# R7FA8M1AH register map
Vendor: Renesas; Series: RA8; File version: 1.2
CPU: CM85 r0p0, little endian, MPU, FPU, VTOR, 4 interrupt priority bits
Registers are 32-bit, read-write, reset 0x0 unless marked. A register's access mark holds for its fields unless they carry their own. Offsets are from the block's base; [hi:lo] are bit positions; {n}, {i} and the like mark numbered series; 'fields as' and 'values as' point back to an identical list.

## USBHS — USB 2.0 High-Speed Module
Base 0x40351000
Same registers: USBHS_NS 0x50351000
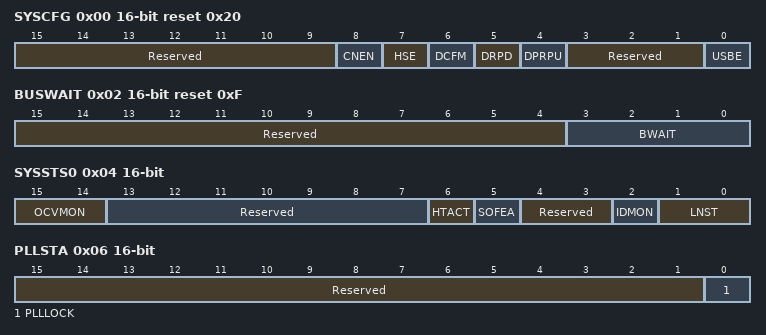
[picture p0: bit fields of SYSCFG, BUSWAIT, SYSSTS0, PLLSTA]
0x00 SYSCFG 16-bit reset 0x20 — System Configuration Control Register
  [15:9] Reserved — These bits are read as 0000000. The write value should be 0000000.
  [8] CNEN — Single End Receiver Enable
    0=Single end receiver operation is disabled; 1=Single end receiver operation is enabled
  [7] HSE — High-Speed Operation Enable
    0=High-speed operation is disabled.(When the function controller function is selected: Full speed, When the host controller function is selected: Full/low speed); 1=High-speed operation is enabled (the controller detects the communication speed)
  [6] DCFM — Controller Function Select
    0=Function controller function is selected; 1=Host controller function is selected
  [5] DRPD — D+/D- Line Resistor Control
    0=Pulling down the line is disabled; 1=Pulling down the line is enabled
  [4] DPRPU — D+ Line Resistor Control
    0=Pulling up the line is disabled; 1=Pulling up the line is enabled
  [3:1] Reserved — These bits are read as 000. The write value should be 000.
  [0] USBE — USB Operation Enable
    0=USB operation is disabled; 1=USB operation is enabled
0x02 BUSWAIT 16-bit reset 0xF (reset mask 0x3F3F) — CPU Bus Wait Register
  [15:4] Reserved — These bits are read as 000000000000. The write value should be 000000000000.
  [3:0] BWAIT — CPU Bus Access Wait Specification BWAIT waits (BWAIT+2 access cycles)
    other=BWAIT (BWAIT wait(s) ( BWAIT + 2 access cycles ))
0x04 SYSSTS0 16-bit ro reset not defined — System Configuration Status Register
  [15:14] OCVMON — External USB1_OVRCURA/USB1_OVRCURB Input Pin MonitorThe OCVMON[1] bit indicates the status of the USBHS_OVRCURA pin. The OCVMON[0] bit indicates the status of the USBHS_OVRCURB pin.
  [13:7] Reserved — These bits are read as 0000000.
  [6] HTACT — Host Sequencer Status Monitor
    0=Host sequencer is stopped; 1=Host sequencer is operating
  [5] SOFEA — SOF Active Monitor While Host Controller Function is Selected.
    0=SOF output is stopped; 1=SOF output is operating
  [4:3] Reserved — These bits are read as 00.
  [2] IDMON — ID0 Pin Monitor
    0=ID0 = Low; 1=ID0 = High
  [1:0] LNST — USB Data Line Status Monitor
    0=SE0 (During Low-Speed Operation:only when the host controller function is selected or During Full-Speed Operation) /Squelch (During Hi-Speed Operation or During Chirp Operation); 1=K-State (During Low-Speed Operation:only when the host controller function is selected) /J-State (During Full-Speed Operation) /Unsquelch (During Hi-Speed Operation) /Chirp J (During Chirp Operation); 2=J-State (During Low-Speed Operation:only when the host controller function is selected) /K-State (During Full-Speed Operation) /Invalid (During Hi-Speed Operation) /Chirp K (During Chirp Operation); 3=SE1 (During Low-Speed Operation:only when the host controller function is selected or During Full-Speed Operation) /Invalid (During Hi-Speed Operation or During Chirp Operation)
0x06 PLLSTA 16-bit ro (reset mask 0x1) — PLL Status Register
  [15:1] Reserved — These bits are read as 000000000000000.
  [0] PLLLOCK — PLL Lock Flag
    0=PLL is not locked; 1=PLL is locked
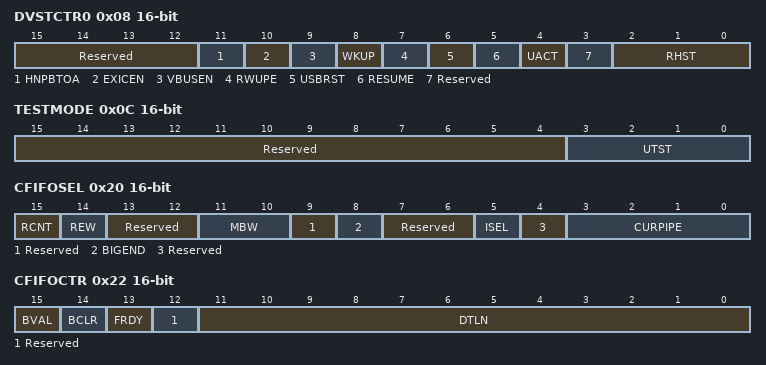
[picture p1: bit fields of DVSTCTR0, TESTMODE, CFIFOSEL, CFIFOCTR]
0x08 DVSTCTR0 16-bit (reset mask 0x7F7) — Device State Control Register 0
  [15:12] Reserved — These bits are read as 0000. The write value should be 0000.
  [11] HNPBTOA — Host Negotiation Protocol (HNP) Control This bit is used when switching from device B to device A while in OTG mode. If the HNPBTOA bit is 1, the internal function control keeps the suspended state until the HNP processing ends even though SYSCFG.DPRPU = 0 or SYSCFG.DCFM = 1 is set.
    0=Normal Operation; 1=Switching from device B to device A is enabled
  [10] EXICEN — USB0_EXICEN Output Pin ControlThe EXICEN bit value is output as the status of the external USB0_EXICEN pin without change.
  [9] VBUSEN — USB0_VBUSEN Output Pin ControlThe VBUSEN bit value is output as the status of the external USB0_VBUSEN pin without change.
  [8] WKUP — Wakeup Output
    0=Remote wakeup signal is not output; 1=Remote wakeup signal is output
  [7] RWUPE — Remote Wakeup Detection Enable
    0=Downstream-port remote wakeup is disabled; 1=Downstream-port remote wakeup is enabled
  [6] USBRST — USB Bus Reset Output
    0=USB bus reset signal is not output; 1=USB bus reset signal is output
  [5] RESUME — Resume Output
    0=Resume signal is not output; 1=Resume signal is output
  [4] UACT — USB Bus Enable
    0=Downstream port is disabled (SOF or micro-SOF transmission is disabled); 1=Downstream port is enabled (SOF or micro-SOF transmission is enabled)
  [3] Reserved — This bit is read as 0. The write value should be 0.
  [2:0] RHST ro — USB Bus Reset Status
    0=Communication speed not determined; 1=Low-speed connection(When the host controller function is selected) /USB bus reset in progress or low-speed connection(When the function controller function is selected); 2=Full-speed connection(When the host controller function is selected) /USB bus reset in progress or full-speed connection(When the function controller function is selected); 3=Setting prohibited; other=others (USB bus reset in progress(When the host controller function is selected))
0x0C TESTMODE 16-bit (reset mask 0xF) — USB Test Mode Register
  [15:4] Reserved — These bits are read as 000000000000. The write value should be 000000000000.
  [3:0] UTST — Test Mode
    0=Normal operation; 1=Test_J TestMode(When the Function Controller Function is Selected); 2=Test_K TestMode(When the Function Controller Function is Selected); 3=Test_SE0_NAK TestMode(When the Function Controller Function is Selected); 4=Test_Packet TestMode(When the Function Controller Function is Selected); 5=Reserved TestMode(When the Function Controller Function is Selected); 6=Reserved TestMode(When the Function Controller Function is Selected); 7=Reserved TestMode(When the Function Controller Function is Selected); 9=Test_J TestMode(When the Host Controller Function is Selected); 10=Test_K TestMode(When the Host Controller Function is Selected); 11=Test_SE0_NAK TestMode(When the Host Controller Function is Selected); 12=Test_Packet TestMode(When the Host Controller Function is Selected); 13=Test_Force_EnableTestMode(When the Host Controller Function is Selected); 14=Reserved TestMode(When the Host Controller Function is Selected); 15=Reserved TestMode(When the Host Controller Function is Selected)
0x14 CFIFO — CFIFO Port Register
  [31:0] FIFOPORT — FIFO Port.Read receive data from the FIFO buffer or write transmit data to the FIFO buffer by accessing these bits.
0x14 CFIFOL 16-bit (alternate view of CFIFO) — CFIFO Port Register L
0x14 CFIFOLL 8-bit (alternate view of CFIFOL) — CFIFO Port Register LL
0x16 CFIFOH 16-bit (alternate view of CFIFO) — CFIFO Port Register H
0x17 CFIFOHH 8-bit (alternate view of CFIFOH) — CFIFO Port Register HH
0x18 D0FIFO — D0FIFO Port Register
  [31:0] FIFOPORT — FIFO Port Read receive data from the FIFO buffer or write transmit data to the FIFO buffer by accessing these bits.
0x18 D0FIFOL 16-bit (alternate view of D0FIFO) — D0FIFO Port Register L
0x18 D0FIFOLL 8-bit (alternate view of D0FIFOL) — D0FIFO Port Register LL
0x1A D0FIFOH 16-bit (alternate view of D0FIFO) — D0FIFO Port Register H
0x1B D0FIFOHH 8-bit (alternate view of D0FIFOH) — D0FIFO Port Register HH
0x1C D1FIFO — D1FIFO Port Register
  [31:0] FIFOPORT — FIFO PortRead receive data from the FIFO buffer or write transmit data to the FIFO buffer by accessing these bits.
0x1C D1FIFOL 16-bit (alternate view of D1FIFO) — D1FIFO Port Register L
0x1C D1FIFOLL 8-bit (alternate view of D1FIFOL) — D1FIFO Port Register LL
0x1E D1FIFOH 16-bit (alternate view of D1FIFO) — D1FIFO Port Register H
0x1F D1FIFOHH 8-bit (alternate view of D1FIFOH) — D1FIFO Port Register HH
0x20 CFIFOSEL 16-bit (reset mask 0xCD27) — CFIFO Port Select Register
  [15] RCNT — Read Count Mode
    0=The DTLN bits are cleared when all of the receive data has been read from the CFIFO; 1=The DTLN bits are decremented each time the receive data is read from the CFIFO
  [14] REW wo — Buffer Pointer Rewind
    0=Do not rewind buffer pointer (Writing 0 has no effect.); 1=Rewind buffer pointer
  [13:12] Reserved — These bits are read as 00. The write value should be 00.
  [11:10] MBW — CFIFO Port Access Bit Width
    0=8-bit width; 1=16-bit width; 2=32-bit width; 3=Setting prohibited
  [9] Reserved — This bit is read as 0. The write value should be 0.
  [8] BIGEND — FIFO Port Endian Control
    0=Little endian; 1=Big endian
  [7:6] Reserved — These bits are read as 00. The write value should be 00.
  [5] ISEL — FIFO Port Access Direction when DCP is Selected
    0=Reading from the buffer memory is selected; 1=Writing to the buffer memory is selected
  [4] Reserved — This bit is read as 0. The write value should be 0.
  [3:0] CURPIPE — FIFO Port Access Pipe Specification
    0=DCP; {v}=PIPE{v} (v=1..9); other=others (Setting prohibited)
0x22 CFIFOCTR 16-bit (reset mask 0xEFFE) — CFIFO Port Control Register
  [15] BVAL — Buffer Memory Valid Flag
    0=Invalid; 1=Writing ended
  [14] BCLR wo — CPU Buffer Clear
    0=No operation; 1=Clear FIFO buffer on the CPU side
  [13] FRDY ro — FIFO Port ReadyIndicates whether the FIFO port can be accessed.
    0=FIFO port access is disabled; 1=FIFO port access is enabled
  [12] Reserved — This bit is read as 0. The write value should be 0.
  [11:0] DTLN ro — Receive Data Length.Indicates the length of the receive data.
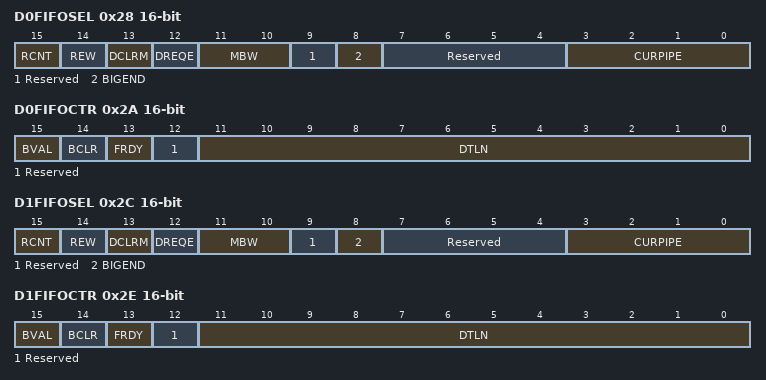
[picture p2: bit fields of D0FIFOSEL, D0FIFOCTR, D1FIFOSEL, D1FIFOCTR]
0x28 D0FIFOSEL 16-bit (reset mask 0xFD07) — D0FIFO Port Select Register
  [15] RCNT — Read Count Mode
    values as CFIFOSEL.RCNT
  [14] REW wo — Buffer Pointer Rewind
    0=The buffer pointer is not rewound; 1=The buffer pointer is rewound
  [13] DCLRM — Auto Buffer Memory Clear Mode Accessed after Specified Pipe Data is Read
    0=Auto buffer clear mode is disabled; 1=Auto buffer clear mode is enabled
  [12] DREQE — UCL_Dx_DREQ Signal Output Enable
    0=Disables the output; 1=Enables the output
  [11:10] MBW — FIFO Port Access Bit Width
    values as CFIFOSEL.MBW
  [9] Reserved — This bit is read as 0. The write value should be 0.
  [8] BIGEND — FIFO Port Endian Control
    0=Little endian; 1=Big endian
  [7:4] Reserved — These bits are read as 0000. The write value should be 0000.
  [3:0] CURPIPE — FIFO Port Access Pipe Specification
    0=No pipe specified; 1=Pipe1; {v}=Pipe {v} (v=2..9); other=others (Setting prohibited)
0x2A D0FIFOCTR 16-bit (reset mask 0xEFFE) — D0FIFO Port Control Register
  fields as CFIFOCTR
0x2C D1FIFOSEL 16-bit (reset mask 0xFD07) — D1FIFO Port Select Register
  [15] RCNT — Read Count Mode
    values as CFIFOSEL.RCNT
  [14] REW wo — Buffer Pointer Rewind
    values as D0FIFOSEL.REW
  [13] DCLRM — Auto Buffer Memory Clear Mode Accessed after Specified Pipe Data is Read
    values as D0FIFOSEL.DCLRM
  [12] DREQE — UCL_Dx_DREQ Signal Output Enable
    0=Disables the output; 1=Enables the output
  [11:10] MBW — FIFO Port Access Bit Width
    values as CFIFOSEL.MBW
  [9] Reserved — This bit is read as 0. The write value should be 0.
  [8] BIGEND — FIFO Port Endian Control
    0=Little endian; 1=Big endian
  [7:4] Reserved — These bits are read as 0000. The write value should be 0000.
  [3:0] CURPIPE — FIFO Port Access Pipe Specification
    0=No pipe specified; {v}=Pipe {v} (v=1..9); other=others (Setting prohibited)
0x2E D1FIFOCTR 16-bit (reset mask 0xEFFE) — D1FIFO Port Control Register
  fields as CFIFOCTR
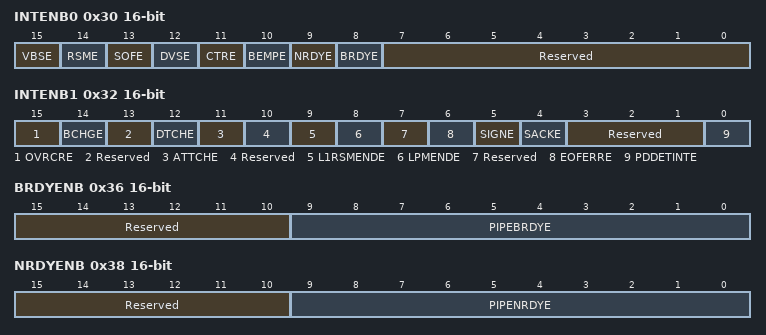
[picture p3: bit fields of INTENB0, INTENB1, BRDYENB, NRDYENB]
0x30 INTENB0 16-bit (reset mask 0xFF00) — Interrupt Enable Register 0
  [15] VBSE — VBUS Interrupt Enable
    0=Interrupt output disabled; 1=Interrupt output enabled
  [14] RSME — Resume Interrupt Enable
    0=Interrupt output disabled; 1=Interrupt output enabled
  [13] SOFE — Frame Number Update Interrupt Enable
    0=Interrupt output disabled; 1=Interrupt output enabled
  [12] DVSE — Device State Transition Interrupt Enable
    0=Interrupt output disabled; 1=Interrupt output enabled
  [11] CTRE — Control Transfer Stage Transition Interrupt Enable
    0=Interrupt output disabled; 1=Interrupt output enabled
  [10] BEMPE — Buffer Empty Interrupt Enable
    0=Interrupt output disabled; 1=Interrupt output enabled
  [9] NRDYE — Buffer Not Ready Response Interrupt Enable
    0=Interrupt output disabled; 1=Interrupt output enabled
  [8] BRDYE — Buffer Ready Interrupt Enable
    0=Interrupt output disabled; 1=Interrupt output enabled
  [7:0] Reserved — These bits are read as 00000000. The write value should be 00000000.
0x32 INTENB1 16-bit (reset mask 0xDB71) — Interrupt Enable Register 1
  [15] OVRCRE — OVRCRE Interrupt Enable
    0=Interrupt output disabled; 1=Interrupt output enabled
  [14] BCHGE — USB Bus Change Interrupt Enable
    0=Interrupt output disabled; 1=Interrupt output enabled
  [13] Reserved — This bit is read as 0. The write value should be 0.
  [12] DTCHE — Disconnection Detection Interrupt Enable
    0=Interrupt output disabled; 1=Interrupt output enabled
  [11] ATTCHE — Connection Detection Interrupt Enable
    0=Interrupt output disabled; 1=Interrupt output enabled
  [10] Reserved — This bit is read as 0. The write value should be 0.
  [9] L1RSMENDE — L1 Resume End Interrupt Enable
    0=Interrupt output disabled; 1=Interrupt output enabled
  [8] LPMENDE — LPM Transaction End Interrupt Enable
    0=Interrupt output disabled; 1=Interrupt output enabled
  [7] Reserved — This bit is read as 0. The write value should be 0.
  [6] EOFERRE — EOF Error Detection Interrupt Enable
    0=Interrupt output disabled; 1=Interrupt output enabled
  [5] SIGNE — Setup Transaction Error Interrupt Enable
    0=Interrupt output disabled; 1=Interrupt output enabled
  [4] SACKE — Setup Transaction Normal Response Interrupt Enable
    0=Interrupt output disabled; 1=Interrupt output enabled
  [3:1] Reserved — These bits are read as 000. The write value should be 000.
  [0] PDDETINTE — PDDETINT Detection Interrupt Enable
    0=Interrupt output disabled; 1=Interrupt output enabled
0x36 BRDYENB 16-bit — BRDY Interrupt Enable Register
  [15:10] Reserved — These bits are read as 000000. The write value should be 000000.
  [9:0] PIPEBRDYE — BRDY Interrupt Enable for Each Pipe
    0=Interrupt output disabled; 1=Interrupt output enabled
0x38 NRDYENB 16-bit — NRDY Interrupt Enable Register
  [15:10] Reserved — These bits are read as 000000. The write value should be 000000.
  [9:0] PIPENRDYE — NRDY Interrupt Enable for Each Pipe
    0=Interrupt output disabled; 1=Interrupt output enabled
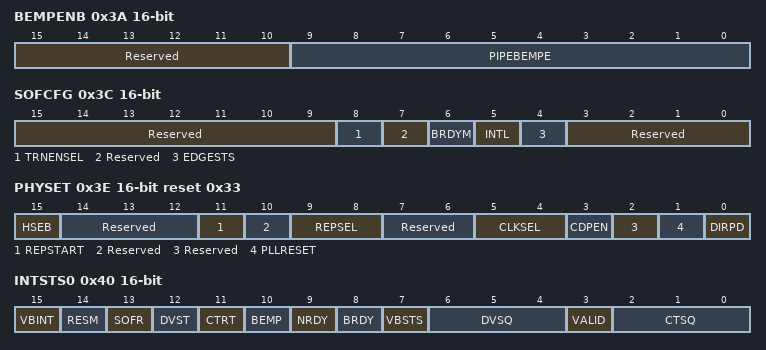
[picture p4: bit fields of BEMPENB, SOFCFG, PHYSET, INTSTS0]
0x3A BEMPENB 16-bit — BEMP Interrupt Enable Register
  [15:10] Reserved — These bits are read as 000000. The write value should be 000000.
  [9:0] PIPEBEMPE — BEMP Interrupt Enable for Each Pipe
    0=Interrupt output disabled; 1=Interrupt output enabled
0x3C SOFCFG 16-bit (reset mask 0x170) — SOF Pin Configuration Register
  [15:9] Reserved — These bits are read as 0000000. The write value should be 0000000.
  [8] TRNENSEL — Transaction-Enabled Time Select.The transfer efficiency can be improved by setting this bit to 1 if no low-speed device is connected directly or via FS-HUB to the USB port.
    0=For non-low-speed communication; 1=For low-speed communication
  [7] Reserved — This bit is read as 0. The write value should be 0.
  [6] BRDYM — PIPEBRDY Interrupt Status Clear Timing.This bit can be set only in the initial setting (before communications).The setting cannot be changed once communication starts.
    0=Software clears the status; 1=Hardware clears the status when data has been read from the FIFO buffer or data has been written to the FIFO buffer
  [5] INTL — Interrupt Output Sense Select
    0=Edge sense; 1=Level sense
  [4] EDGESTS ro — Interrupt Edge Processing Status Monitor
    0=Interrupt edge processing is not run; 1=Interrupt edge processing is running
  [3:0] Reserved — These bits are read as 0000. The write value should be 0000.
0x3E PHYSET 16-bit reset 0x33 (reset mask 0x8B3B) — PHY Setting Register
  [15] HSEB — CL-Only Mode
    0=CL-only mode is not activated; 1=CL-only mode is activated
  [14:12] Reserved — These bits are read as 000. The write value should be 000.
  [11] REPSTART — Forcibly Start Terminating Resistance Adjustment
    0=Terminating resistance adjustment is forcibly started; 1=Terminating resistance adjustment is not forcibly started
  [10] Reserved — This bit is read as 0. The write value should be 0.
  [9:8] REPSEL — Terminating Resistance Adjustment Cycle
    0=No cycle is set; 1=Adjust terminating resistance at 16-second intervals; 2=Adjust terminating resistance at 64-second intervals; 3=Adjust terminating resistance at 128-second intervals
  [7:6] Reserved — These bits are read as 00. The write value should be 00.
  [5:4] CLKSEL — Input System Clock Frequency
    0=Setting Prohibited; 1=12 MHz; 2=20 MHz; 3=24 MHz
  [3] CDPEN — Charging Downstream Port Enable
    0=Disable charging downstream port; 1=Enable charging downstream port
  [2] Reserved — This bit is read as 0. The write value should be 0.
  [1] PLLRESET — PLL Reset Control
    0=Disable PLL reset control for UTMI_PHY; 1=Enable PLL reset control for UTMI_PHY
  [0] DIRPD — Power-Down Control
    0=Does not enter low-power consumption mode; 1=Enter low-power consumption mode
0x40 INTSTS0 16-bit (reset mask 0xFF7F) — Interrupt Status Register 0
  [15] VBINT — VBUS Interrupt Status
    0=VBUS interrupt is not generated on detecting a change in the USBHS_VBUS pin; 1=VBUS interrupt is generated on detecting a change in the USBHS_VBUS pin
  [14] RESM — Resume Interrupt Status
    0=Resume interrupts are not generated; 1=Resume interrupts are generated
  [13] SOFR — Frame Number Refresh Interrupt Status
    0=SOF interrupts are not generated; 1=SOF interrupts are generated
  [12] DVST — Device State Transition Interrupt Status
    0=Device state transition interrupts are not generated; 1=Device state transition interrupts are generated
  [11] CTRT — Control Transfer Stage Transition Interrupt Status
    0=Control transfer stage transition interrupts are not generated; 1=Control transfer stage transition interrupts are generated
  [10] BEMP ro — Buffer Empty Interrupt Status
    0=BEMP interrupts are not generated; 1=BEMP interrupts are not generated
  [9] NRDY ro — Buffer Not Ready Interrupt Status
    0=NRDY interrupts are not generated; 1=NRDY interrupts are generated
  [8] BRDY ro — Buffer Ready Interrupt Status
    0=BRDY interrupts are not generated; 1=BRDY interrupts are generated
  [7] VBSTS ro — VBUS Input Status
    0=The USBHS_VBUS pin is low; 1=The USBHS_VBUS pin is high
  [6:4] DVSQ ro — Device State
    0=Powered state; 1=Default state; 2=Address state; 3=Configured state; other=others (Suspended state(1xx))
  [3] VALID — USB Request Reception
    0=Not detected; 1=Setup packet reception
  [2:0] CTSQ ro — Control Transfer Stage
    0=Idle or setup stage; 1=Control read data stage; 2=Control read status stage; 3=Control write data stage; 4=Control write status stage; 5=Control write (no data) status stage; 6=Control transfer sequence error; 7=Setting prohibited
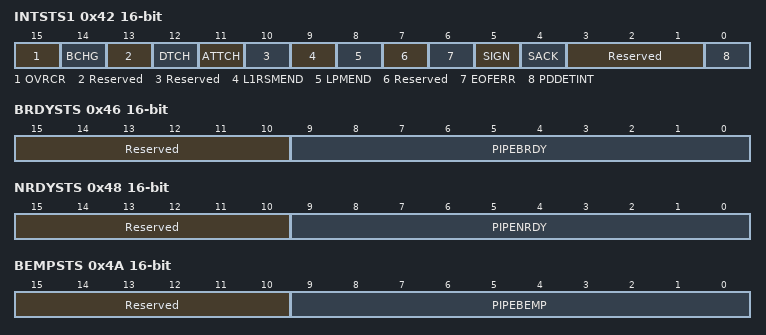
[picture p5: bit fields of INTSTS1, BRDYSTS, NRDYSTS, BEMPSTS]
0x42 INTSTS1 16-bit (reset mask 0xDB71) — Interrupt Status Register 1
  [15] OVRCR write-0-clears read-modifies — Overcurrent Interrupt Status
    0=OVRCR interrupts are not generated; 1=OVRCR interrupts are generated
  [14] BCHG write-0-clears read-modifies — USB Bus Change Interrupt Status
    0=BCHG interrupts are not generated; 1=BCHG interrupts are generated
  [13] Reserved — This bit is read as 0. The write value should be 0.
  [12] DTCH write-0-clears read-modifies — USB Disconnection Detection Interrupt Status
    0=DTCH interrupts are not generated; 1=DTCH interrupts are generated
  [11] ATTCH write-0-clears read-modifies — USB Connection Detection Interrupt Status
    0=ATTCH interrupts are not generated; 1=ATTCH interrupts are generated
  [10] Reserved — This bit is read as 0. The write value should be 0.
  [9] L1RSMEND write-0-clears read-modifies — L1 Resume End Interrupt Status
    0=L1RSMEND interrupts are not generated; 1=L1RSMEND interrupts are generated
  [8] LPMEND write-0-clears read-modifies — LPM Transaction End Interrupt Status
    0=LPMEND interrupts are not generated; 1=LPMEND interrupts are generated
  [7] Reserved — This bit is read as 0. The write value should be 0.
  [6] EOFERR write-0-clears read-modifies — EOF Error Detection Interrupt Status
    0=EOFERR interrupts are not generated; 1=EOFERR interrupts are generated
  [5] SIGN write-0-clears read-modifies — Setup Transaction Error Interrupt Status
    0=SIGN interrupts are not generated; 1=SIGN interrupts are generated
  [4] SACK write-0-clears read-modifies — Setup Transaction Normal Response Interrupt Status
    0=SACK interrupts are not generated; 1=SACK interrupts are generated
  [3:1] Reserved — These bits are read as 000. The write value should be 000.
  [0] PDDETINT write-0-clears read-modifies — PDDET Detection Interrupt Status
    0=PDDET interrupts are not generated; 1=PDDET interrupts are generated
0x46 BRDYSTS 16-bit — BRDY Interrupt Status Register
  [15:10] Reserved — These bits are read as 000000. The write value should be 000000.
  [9:0] PIPEBRDY — BRDY Interrupt Status for Each Pipe
    0=Interrupts are not generated; 1=Interrupts are generated
0x48 NRDYSTS 16-bit — NRDY Interrupt Status Register
  [15:10] Reserved — These bits are read as 000000. The write value should be 000000.
  [9:0] PIPENRDY — NRDY Interrupt Status for Each Pipe
    0=Interrupts are not generated; 1=Interrupts are generated
0x4A BEMPSTS 16-bit — BEMP Interrupt Status Register
  [15:10] Reserved — These bits are read as 000000. The write value should be 000000.
  [9:0] PIPEBEMP — BEMP Interrupt Status for Each Pipe
    0=Interrupts are not generated; 1=Interrupts are generated
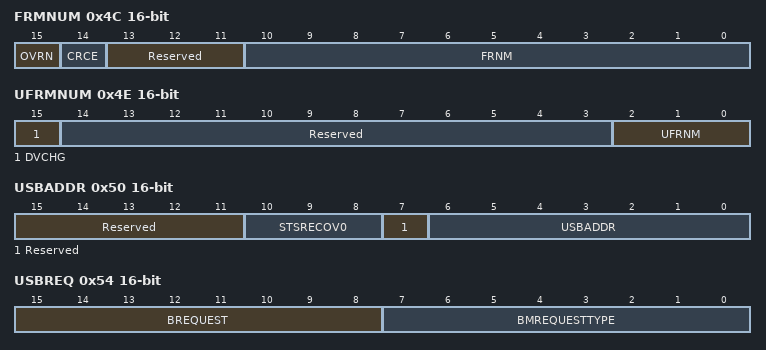
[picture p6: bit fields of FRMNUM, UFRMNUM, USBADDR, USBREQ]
0x4C FRMNUM 16-bit (reset mask 0xC7FF) — Frame Number Register
  [15] OVRN — Overrun/Underrun Detection Status
    0=No error; 1=An error occurred
  [14] CRCE — CRC Error Detection Status
    0=No error; 1=An error occurred
  [13:11] Reserved — These bits are read as 000. The write value should be 000.
  [10:0] FRNM ro — Frame Number.Indicate the latest frame number.
0x4E UFRMNUM 16-bit (reset mask 0x7) — uFrame Number Register
  [15] DVCHG — Device State Change
    0=Disables the writing to the USBADDR.STSRECOV0[2:0] bits and USBADDR.USBADDR[6:0]; 1=Enables the writing to the USBADDR.STSRECOV0[2:0] bits and USBADDR.USBADDR[6:0]
  [14:3] Reserved — These bits are read as 000000000000. The write value should be 000000000000.
  [2:0] UFRNM ro — MicroframeIndicate the microframe number.
0x50 USBADDR 16-bit (reset mask 0x7F) — USB Address Register
  [15:11] Reserved — These bits are read as 00000. The write value should be 00000.
  [10:8] STSRECOV0 — Status Recovery
    1=Return to the full-speed state(bits DVSTCTR0.RHST[2:0] = 010b), bits INTSTS0.DVSQ[2:0] = 001b (Default state)(function controller selected); 2=Return to the full-speed state (bits DVSTCTR0.RHST[2:0] = 010b), bits INTSTS0.DVSQ[2:0] = 010b (Address state)(function controller selected)/ Return to the low-speed state (bitsDVSTCTR0.RHST[2:0] = 001b)(host controller is selected); 3=Return to the full-speed state (bits DVSTCTR0.RHST[2:0] = 010b), bits INTSTS0.DVSQ[2:0] = 011b (Configured state)(function controller selected); 4=Return to the full-speed state (bits DVSTCTR0.RHST[2:0] = 010b)(host controller selected); 5=Return to the high-speed state (bits DVSTCTR0.RHST[2:0] = 011b), bits INTSTS0.DVSQ[2:0] = 001b (Default state)(function controller selected); 6=Return to the high-speed state (bits DVSTCTR0.RHST[2:0] = 011b), bits INTSTS0.DVSQ[2:0] = 010b (Address state)(function controller selected)/ Return to the high-speed state (bits DVSTCTR0.RHST[2:0] = 011b)(host controller selected); 7=Return to the high-speed state (bits DVSTCTR0.RHST[2:0] = 011b), bits INTSTS0.DVSQ[2:0] = 011b (Configured state)(function controller selected); other=others (Setting prohibited.)
  [7] Reserved — This bit is read as 0. The write value should be 0.
  [6:0] USBADDR — USB AddressWhen the function controller function is selected, these bits indicate the USB address assigned by the host.
0x54 USBREQ 16-bit — USB Request Type Register
  [15:8] BREQUEST — USB request bRequest value Finction controller selected : read-only Host controller selected : read-write
  [7:0] BMREQUESTTYPE — USB request bmRequestType value Finction controller selected : read-only Host controller selected : read-write
0x56 USBVAL 16-bit — USB Request Value Register
  [15:0] WVALUE — Value of USB request wValue Finction controller selected : read-only Host controller selected : read-write
0x58 USBINDX 16-bit — USB Request Index Register
  [15:0] WINDEX — Value of USB request wIndex Finction controller selected : read-only Host controller selected : read-write
0x5A USBLENG 16-bit — USB Request Length Register
  [15:0] WLENGTH — Value of USB request wLength Finction controller selected : read-only Host controller selected : read-write
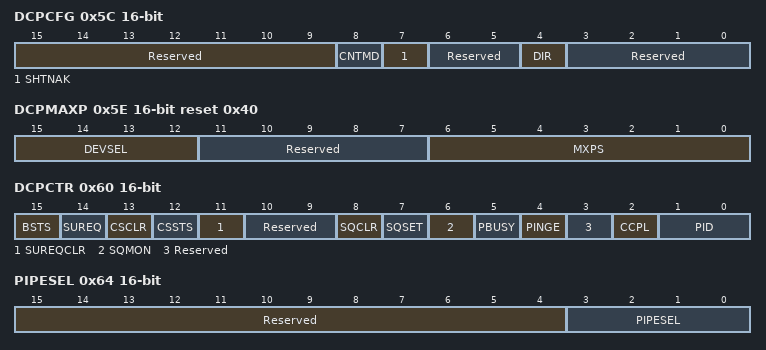
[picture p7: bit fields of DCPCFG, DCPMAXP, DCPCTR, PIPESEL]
0x5C DCPCFG 16-bit (reset mask 0x190) — DCP Configuration Register
  [15:9] Reserved — These bits are read as 0000000. The write value should be 0000000.
  [8] CNTMD — Continuous Transfer Mode
    0=Non-continuous transfer mode; 1=Continuous transfer mode
  [7] SHTNAK — Pipe Blocking on End of Transfer
    0=The pipe remains open after transfer ends; 1=The pipe is blocked after transfer ends
  [6:5] Reserved — These bits are read as 00. The write value should be 00.
  [4] DIR — Transfer Direction
    0=Data receiving direction; 1=Data transmitting direction
  [3:0] Reserved — These bits are read as 0000. The write value should be 0000.
0x5E DCPMAXP 16-bit reset 0x40 (reset mask 0xF07F) — DCP Maximum Packet Size Register
  [15:12] DEVSEL — Device SelectThese bits specify the address of the destination function device for control transfer when the host controller function is selected.
    0=Address 0000; 1=Address 0001; 2=Address 0010; 3=Address 0011; 4=Address 0100; 5=Address 0101; other=others (setting prohibited)
  [11:7] Reserved — These bits are read as 00000. The write value should be 00000.
  [6:0] MXPS — Maximum Packet SizeThese bits specify the maximum data payload (maximum packet size) for the DCP.
0x60 DCPCTR 16-bit (reset mask 0xF1F7) — DCP Control Register
  [15] BSTS ro — Buffer Status
    0=Buffer access is disabled; 1=Buffer access is enabled
  [14] SUREQ — SETUP Token Transmission
    0=Writing is ignored; 1=Transmits the setup packet
  [13] CSCLR — Split Transaction CSPLIT Status Clear
    0=Writing is ignored; 1=Clears the CSSTS bit to 0
  [12] CSSTS ro — Split Transaction COMPLETE SPLIT(CSPLIT) Status
    0=START-SPLIT(SSPLIT) transaction processing is in progress or processing for devices that do not use Split Transaction is in progress; 1=The CSPLIT transaction processing is in progress
  [11] SUREQCLR — SUREQ Bit Clear
    0=Writing is ignored; 1=Clears the SUREQ bit to 0
  [10:9] Reserved — These bits are read as 00. The write value should be 00.
  [8] SQCLR — Toggle Bit Clear
    0=Writing is ignored; 1=Specifies DATA0
  [7] SQSET — Toggle Bit Set
    0=Writing is ignored; 1=Specifies DATA1
  [6] SQMON ro — Sequence Toggle Bit Monitor
    0=DATA0; 1=DATA1
  [5] PBUSY ro — Pipe Busy
    0=The relevant pipe is not used for the USB bus; 1=The relevant pipe is in use for the USB bus
  [4] PINGE — PING Token Issue Enable
    0=Issuing PING token is disabled; 1=Normal PING operation
  [3] Reserved — This bit is read as 0. The write value should be 0.
  [2] CCPL — Control Transfer End Enable
    0=Completion of control transfer is disabled; 1=Completion of control transfer is enabled
  [1:0] PID — Response PID
    0=NAK response; 1=BUF response (depending on buffer state); 2=STALL response; 3=STALL response
0x64 PIPESEL 16-bit (reset mask 0xF) — Pipe Window Select Register
  [15:4] Reserved — These bits are read as 000000000000. The write value should be 000000000000.
  [3:0] PIPESEL — Pipe Window SelectThese bits specify the pipe for registers at addresses 68H to 6EH.
    0=No pipe selected; {v}=PIPE{v} (v=1..9); other=others (setting prohibited)
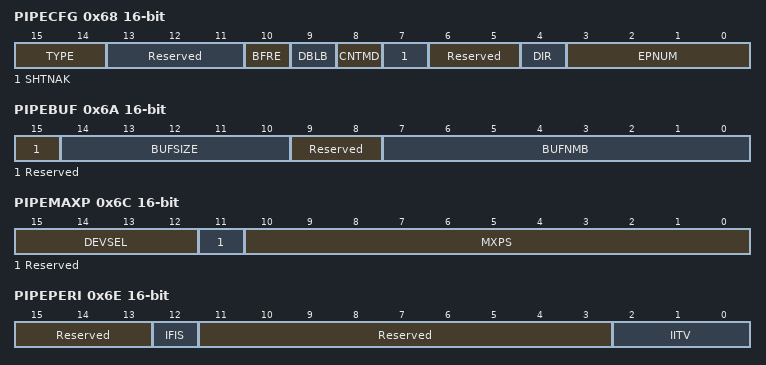
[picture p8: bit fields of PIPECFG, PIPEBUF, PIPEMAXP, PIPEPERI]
0x68 PIPECFG 16-bit (reset mask 0xC79F) — Pipe Configuration Register
  [15:14] TYPE — Transfer Type
    0=Pipe not used; 1=Bulk transfer; 2=Interrupt transfer; 3=Isochronous transfer
  [13:11] Reserved — These bits are read as 000. The write value should be 000.
  [10] BFRE — BRDY Interrupt Operation Specification
    0=BRDY interrupt upon transmitting or receiving data; 1=BRDY interrupt upon completion of reading data
  [9] DBLB — Double Buffer Mode
    0=Single buffer; 1=Double buffer
  [8] CNTMD — Continuous Transfer Mode
    0=Discontinuous transfer mode; 1=Continuous transfer mode
  [7] SHTNAK — Pipe Disabled at End of Transfer
    0=The pipe is continued at the end of transfer; 1=The pipe is disabled at the end of transfer
  [6:5] Reserved — These bits are read as 00. The write value should be 00.
  [4] DIR — Transfer Direction
    0=Receiving direction; 1=Transmitting direction
  [3:0] EPNUM — Endpoint Number
    0=the selected pipe is not used; other=others (specify the endpoint number for the selected pipe.)
0x6A PIPEBUF 16-bit (reset mask 0x7CFF) — Pipe Buffer Register
  [15] Reserved — This bit is read as 0. The write value should be 0.
  [14:10] BUFSIZE — Buffer Size 00h: 64 bytes 01h: 128 bytes : 1Fh: 2 Kbytes
    other=BUFSIZE (( BUFSIZE + 1 ) x 64 kbytes)
  [9:8] Reserved — These bits are read as 00. The write value should be 00.
  [7:0] BUFNMB range 0x04..0x87 — Buffer NumberThese bits specify the FIFO buffer number of the selected pipe (04h to 87h).
    other=BUFNMB (specify the FIFO buffer number of the selected pipe (04h to 87h).)
0x6C PIPEMAXP 16-bit (reset mask 0xF7FF) — Pipe Maximum Packet Size Register
  [15:12] DEVSEL range 0x0..0xA — Device SelectThese bits specify the address of the peripheral device when the host controller function is selected.
    other=DEVSEL (Address=DEVSEL)
  [11] Reserved — This bit is read as 0. The write value should be 0.
  [10:0] MXPS range 0x01..0x40 — Maximum Packet SizeThese bits specify the maximum data payload (maximum packet size) for the selected pipe.A size of 1h to 40h bytes can be set for PIPE6 to PIPE9.
    other=MXPS (Maximum packet size)
0x6E PIPEPERI 16-bit (reset mask 0x1007) — Pipe Cycle Control Register
  [15:13] Reserved — These bits are read as 000. The write value should be 000.
  [12] IFIS — Isochronous IN Buffer Flush
    0=The buffer is not flushed; 1=The buffer is flushed
  [11:3] Reserved — These bits are read as 000000000. The write value should be 000000000.
  [2:0] IITV — Interval Error Detection IntervalThese bits specify the transfer interval timing for the selected pipe as n-th power of 2 of the frame timing.
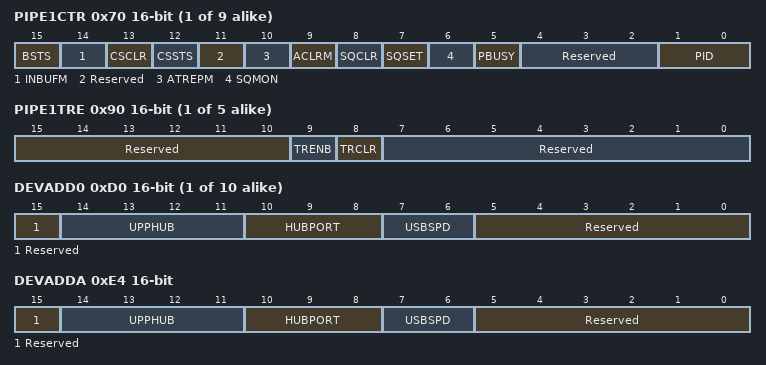
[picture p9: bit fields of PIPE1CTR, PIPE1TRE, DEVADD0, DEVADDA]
{0x6E+2i} PIPE{i}CTR (i=1..9) 16-bit (reset mask 0xF7E3) — PIPE Control Register
  [15] BSTS ro — Buffer StatusThis bit indicates the FIFO buffer status for the relevant pipe.
    0=Buffer access is disabled; 1=Buffer access is enabled
  [14] INBUFM ro — Transmit Buffer MonitorThis bit indicates the FIFO buffer status for the relevant pipe in the transmitting direction.
    0=No transmittable data is present in the FIFO buffer; 1=Transmittable data is present in the FIFO buffer
  [13] CSCLR — CSPLIT Status ClearSet this bit to 1 when clearing the CSSTS bit of the relevant pipe
    0=Writing is disabled; 1=The CSSTS bit is cleared
  [12] CSSTS ro — CSSTS StatusThis bit indicates the CSPLIT status of Split Transaction of the relevant pipe
    0=SSplit Transaction processing is in progress or transfer without Split Transaction is in progress; 1=CSplit Transaction processing is in progress
  [11] Reserved — This bit is read as 0. The write value should be 0.
  [10] ATREPM — Auto Response ModeThis bit enables or disables auto response mode for the relevant pipe.
    0=Auto response mode is disabled; 1=Auto response mode is enabled (Transmission: zero-length packet response, Reception: NAK response and NRDY interrupt)
  [9] ACLRM — Auto Buffer Clear ModeThis bit enables or disables auto buffer clear mode for the relevant pipe
    0=Disabled; 1=Enabled (all buffers are initialized)
  [8] SQCLR — Toggle Bit ClearThis bit is set to 1 when the expected value of the sequence toggle bit for the next transaction of the relevant pipe is cleared to DATA0
    0=Writing is ignored; 1=Specifies DATA0
  [7] SQSET — Toggle Bit SetThis bit is set to 1 when the expected value of the sequence toggle bit for the next transaction of the relevant pipe is set for DATA1
    0=Writing is ignored; 1=Specifies DATA1
  [6] SQMON ro — Toggle Bit ConfirmationThis bit indicates the expected value of the sequence toggle bit for the next transaction of the relevant pipe
    0=DATA0; 1=DATA1
  [5] PBUSY ro — Pipe BusyThis bit indicates whether the relevant pipe is being used for the USB bus
    values as DCPCTR.PBUSY
  [4:2] Reserved — These bits are read as 000. The write value should be 000.
  [1:0] PID — Response PIDThese bits specify the response type for the next transaction of the relevant pipe.
    values as DCPCTR.PID
{0x8C+4i} PIPE{i}TRE (i=1..5) 16-bit (reset mask 0x300) — PIPE Transaction Counter Enable Register
  [15:10] Reserved — These bits are read as 000000. The write value should be 000000.
  [9] TRENB — Transaction Counter EnableEnables or disables the transaction counter function.
    0=The transaction counter function is disabled; 1=The transaction counter function is enabled
  [8] TRCLR — Transaction Counter ClearSetting this bit to 1 allows clearing the transaction counter to 0.
    0=Invalid; 1=The current counter value is cleared
  [7:0] Reserved — These bits are read as 00000000. The write value should be 00000000.
{0x8E+4i} PIPE{i}TRN (i=1..5) 16-bit — PIPE Transaction Counter Register
  [15:0] TRNCNT — Transaction CounterWhen writing to: Specify the number of total packets (number of transactions) to be received by the relevant PIPE.When read from: When TRENB = 0: Indicate the specified number of transactions.When TRENB = 1: Indicate the number of currently counted transactions.
{0xD0+2i} DEVADD{i} (i=0..9) 16-bit (reset mask 0x7FC0) — Device Address Configuration Register
  [15] Reserved — This bit is read as 0. The write value should be 0.
  [14:11] UPPHUB range 0x0000..0x1010 — Communication Target Connecting Hub Register
    0=Directly connected to the port of the USBHS; other=UPPHUB (USB address of the hub)
  [10:8] HUBPORT — Communication Target Connecting Hub Port
    0=Directly connected to the port of the USBHS; other=others (Port number of the hub)
  [7:6] USBSPD — Transfer Speed of Communication Target Device
    0=DEVADDx is not used; 1=Low speed; 2=Full speed; 3=High speed
  [5:0] Reserved — These bits are read as 000000. The write value should be 000000.
0xE4 DEVADDA 16-bit (reset mask 0x7FC0) — Device Address Configuration Register A
  [15] Reserved — This bit is read as 0. The write value should be 0.
  [14:11] UPPHUB range 0x0000..0x1010 — Communication Target Connecting Hub Register
    values as DEVADD0.UPPHUB
  [10:8] HUBPORT — Communication Target Connecting Hub Port
    values as DEVADD0.HUBPORT
  [7:6] USBSPD — Transfer Speed of Communication Target Device
    0=DEVADDA is not used; 1=Low speed; 2=Full speed; 3=High speed
  [5:0] Reserved — These bits are read as 000000. The write value should be 000000.
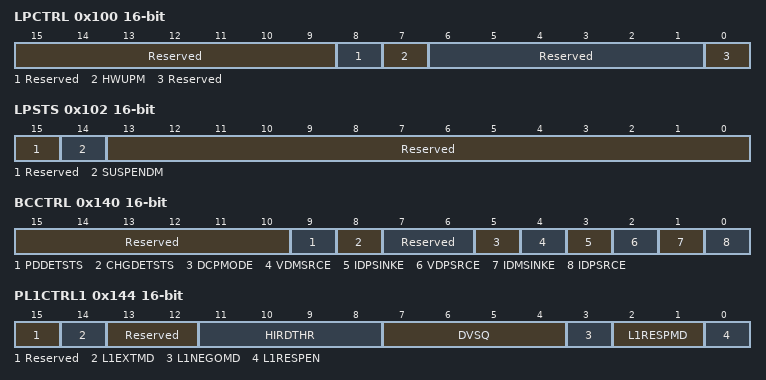
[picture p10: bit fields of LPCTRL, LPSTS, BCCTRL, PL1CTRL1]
0x100 LPCTRL 16-bit (reset mask 0x81) — Low Power Control Register
  [15:9] Reserved — These bits are read as 0000000. The write value should be 0000000.
  [8] Reserved — This bit is read as 0. The write value should be 0.
  [7] HWUPM — Hardware return made control
    0=Hardware return is not made while the CPU clock is inactive; 1=Hardware return is made while the CPU clock is inactive
  [6:1] Reserved — These bits are read as 000000. The write value should be 000000.
  [0] Reserved — This bit is read as 0. The write value should be 0.
0x102 LPSTS 16-bit (reset mask 0x4000) — Low Power Status Register
  [15] Reserved — This bit is read as 0. The write value should be 0.
  [14] SUSPENDM — UTMI SuspendM ControlThis bit controls the SuspendM signal to the PHY designed under the UTMI specification.
    0=UTMI suspension mode; 1=UTMI normal mode
  [13:0] Reserved — These bits are read as 00000000000000. The write value should be 00000000000000.
0x140 BCCTRL 16-bit (reset mask 0x33F) — Battery Charging Control Register
  [15:10] Reserved — These bits are read as 000000. The write value should be 000000.
  [9] PDDETSTS ro — PDDET Status
    0=The PDDET pin is at low level; 1=The PDDET pin is at high level
  [8] CHGDETSTS ro — CHGDET Status
    0=The CHGDET pin is at low level; 1=The CHGDET pin is at high level
  [7:6] Reserved — These bits are read as 00. The write value should be 00.
  [5] DCPMODE — DCP Mode Control
    0=The RDCP_DAT resistor is disabled; 1=The RDCP_DAT resistor is enabled
  [4] VDMSRCE — VDMSRC Control
    0=The VDM_SRC circuit is disabled. (Initial value); 1=The VDM_SRC circuit is enabled
  [3] IDPSINKE — IDPSINK Control
    0=The IDP_SINK circuit is disabled. (Initial value); 1=The IDP_SINK circuit is enabled
  [2] VDPSRCE — VDPSRC Control
    0=The VDP_SRC circuit is disabled. (Initial value); 1=The VDP_SRC circuit is enabled
  [1] IDMSINKE — IDMSINK Control
    0=The IDM_SINK circuit is disabled. (Initial value); 1=The IDM_SINK circuit is enabled
  [0] IDPSRCE — IDPSRC Control
    0=The IDP_SRC circuit is disabled. (Initial value); 1=The IDP_SRC circuit is enabled
0x144 PL1CTRL1 16-bit (reset mask 0x4FFF) — Function L1 Control Register 1
  [15] Reserved — This bit is read as 0. The write value should be 0.
  [14] L1EXTMD — PHY Control Mode at L1 Return
    0=SUSPENDM is not set by hardware when Host K is received; 1=SUSPENDM is set by hardware when Host K is received
  [13:12] Reserved — These bits are read as 00. The write value should be 00.
  [11:8] HIRDTHR — L1 Response Negotiation Threshold ValueHIRD threshold value used for L1NEGOMD.The format is the same as the HIRD field in HL1CTRL.
  [7:4] DVSQ ro — DVSQ Extension.DVSQ[3] is Mirror of DVSQ[2:0] in INTSTS0.Indicates the L1 state together with the device state bits DVSQ[2:0].
    0=Powered state; 1=Default state; 2=Address state; 3=Configured state; {v}=Suspended state (v=4..7); {v}=L1 state (v=8..11); other=others (setting prohibited)
  [3] L1NEGOMD — L1 Response Negotiation Control.NOTE: This bit is valid only when the L1RESPMD[1:0] value is 2'b11.
    0=When receive HIRD is larger than HIRDTHR[3:0], ACK response is returned. In other cases (including HIRD = HIRDTHR[3:0]), NYET response is returned.; 1=When receive HIRD is smaller than HIRDTHR[3:0], ACK response is returned. In other cases (including HIRD = HIRDTHR[3:0]), NYET response is returned.
  [2:1] L1RESPMD — L1 Response Mode
    0=NYET; 1=ACK; 2=STALL; 3=According to the L1NEGOMD bit
  [0] L1RESPEN — L1 Response Enable
    0=LPM is not supported; 1=LPM is supported
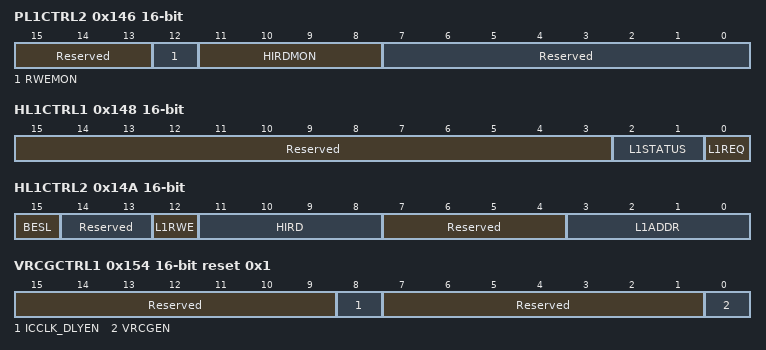
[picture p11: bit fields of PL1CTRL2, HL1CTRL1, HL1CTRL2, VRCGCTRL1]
0x146 PL1CTRL2 16-bit (reset mask 0x1F00) — Function L1 Control Register 2
  [15:13] Reserved — These bits are read as 000. The write value should be 000.
  [12] RWEMON — RWE Value Monitor
    0=The RWE bit value of the LPM token received last is reflected; 1=The RWE bit value of the LPM token received last is reflected
  [11:8] HIRDMON — HIRD Value Monitor
    0=The HIRD field value of the LPM token received last is reflected; 1=The HIRD field value of the LPM token received last is reflected
  [7:0] Reserved — These bits are read as 00000000. The write value should be 00000000.
0x148 HL1CTRL1 16-bit (reset mask 0x7) — Host L1 Control Register 1
  [15:3] Reserved — These bits are read as 0000000000000. The write value should be 0000000000000.
  [2:1] L1STATUS — L1 Request Completion Status
    0=ACK received; 1=NYET received; 2=STALL received; 3=Transaction error
  [0] L1REQ — L1 Transition Request
    0=This bit is cleared to 0 by hardware when the LPM transaction is completed; 1=To make a transition to the L1 state
0x14A HL1CTRL2 16-bit (reset mask 0x9F0F) — Host L1 Control Register 2
  [15] BESL — BESL & Alternate HIRDThis bit selects the K-State drive period at the time of L1 Resume.
  [14:13] Reserved — These bits are read as 00. The write value should be 00.
  [12] L1RWE — LPM Token L1 RemoteWake EnableThese bits specify the value to be set in the RWE field of LPM token.
  [11:8] HIRD — LPM Token HIRD
    0=50 us(Setting prohibited(BESL = 0)) / 75 us(BESL = 1); 1=125 us(BESL = 0) / 100 us(BESL = 1); 2=200 us(BESL = 0) / 150 us(BESL = 1); 3=275 us(BESL = 0) / 250 us(BESL = 1); 4=350 us(BESL = 0) / 350 us(BESL = 1); 5=425 us(BESL = 0) / 450 us(BESL = 1); 6=500 us(BESL = 0) / 950 us(BESL = 1); 7=575 us(BESL = 0) / 1950 us(BESL = 1); 8=650 us(BESL = 0) / 2950 us(BESL = 1); 9=725 us(BESL = 0) / 3950 us(BESL = 1); 10=800 us(BESL = 0) / 4950 us(BESL = 1); 11=875 us(BESL = 0) / 5950 us(BESL = 1); 12=950 us(BESL = 0) / 6950 us(BESL = 1); 13=1025 us(Setting prohibited(BESL = 0)) / 7950 us(BESL = 1); 14=1100 us(Setting prohibited(BESL = 0)) / 8950 us(BESL = 1); 15=1175 us(Setting prohibited(BESL = 0)) / 9950 us(BESL = 1)
  [7:4] Reserved — These bits are read as 0000. The write value should be 0000.
  [3:0] L1ADDR — LPM Token DeviceAddressThese bits specify the value to be set in the ADDR field of LPM token.
0x154 VRCGCTRL1 16-bit reset 0x1 — VRCORE CG Control Register 1
  [15:9] Reserved — These bits are read as 0000000. The write value should be 0000000.
  [8] ICCLK_DLYEN — ICCLK delay enable
    0=disabled; 1=enabled
  [7:1] Reserved — These bits are read as 0000000. The write value should be 0000000.
  [0] VRCGEN — Clock gating for VRCORE Enable
    0=disabled; 1=enabled
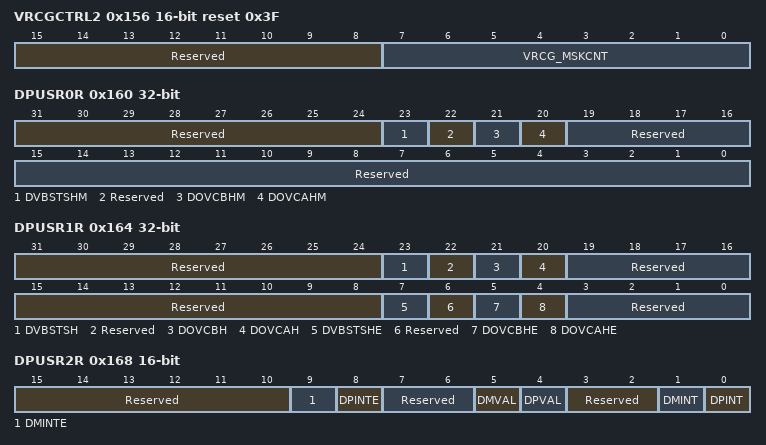
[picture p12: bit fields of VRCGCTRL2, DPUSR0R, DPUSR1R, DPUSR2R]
0x156 VRCGCTRL2 16-bit reset 0x3F — VRCORE CG Control Register 2
  [15:8] Reserved — These bits are read as 00000000. The write value should be 00000000.
  [7:0] VRCG_MSKCNT — Clocking mask count for VRCORE
0x160 DPUSR0R ro (reset mask 0xFF4FFFFF) — Deep Standby USB Transceiver Control/Pin Monitor Register
  [31:24] Reserved — These bits are read as 00000000.
  [23] DVBSTSHM — VBUS InputIndicates VBUS input signal on the HS side of USB port.
  [22] Reserved — This bit is read as 0.
  [21] DOVCBHM — OVRCURB InputIndicates OVRCURB input signal on the HS side of USB port.
  [20] DOVCAHM — OVRCURA InputIndicates OVRCURA input signal on the HS side of USB port.
  [19:0] Reserved — These bits are read as 00000000000000000000.
0x164 DPUSR1R — Deep Standby USB Suspend/Resume Interrupt Register
  [31:24] Reserved — These bits are read as 00000000. The write value should be 00000000.
  [23] DVBSTSH ro — Indication of Return from VBUS Interrupt Source
    0=Indicates deep software standby mode; 1=Indicates return from deep software standby mode
  [22] Reserved — This bit is read as 0. The write value should be 0.
  [21] DOVCBH ro — Indication of Return from OVRCURB Interrupt Source
    values as DVBSTSH
  [20] DOVCAH ro — Indication of Return from OVRCURA Interrupt Source
    values as DVBSTSH
  [19:16] Reserved — These bits are read as 0000. The write value should be 0000.
  [15:8] Reserved — These bits are read as 00000000. The write value should be 00000000.
  [7] DVBSTSHE — VBUS Interrupt Enable/Clear
    0=Disables return from deep software standby mode; 1=Enables return from deep software standby mode
  [6] Reserved — This bit is read as 0. The write value should be 0.
  [5] DOVCBHE — OVRCURB Interrupt Enable Clear
    values as DVBSTSHE
  [4] DOVCAHE — OVRCURA Interrupt Enable Clear
    values as DVBSTSHE
  [3:0] Reserved — These bits are read as 0000. The write value should be 0000.
0x168 DPUSR2R 16-bit — Deep Standby USB Suspend/Resume Interrupt Register
  [15:10] Reserved — These bits are read as 000000. The write value should be 000000.
  [9] DMINTE — DM Interrupt Enable Clear
    values as DPUSR1R.DVBSTSHE
  [8] DPINTE — DP Interrupt Enable Clear
    values as DPUSR1R.DVBSTSHE
  [7:6] Reserved — These bits are read as 00. The write value should be 00.
  [5] DMVAL ro — DM InputIndicates DM input signal on the HS side of USB port.
  [4] DPVAL ro — DP InputIndicates DP input signal on the HS side of USB port.
  [3:2] Reserved — These bits are read as 00. The write value should be 00.
  [1] DMINT ro — Indication of Return from DM Interrupt Source
    values as DPUSR1R.DVBSTSH
  [0] DPINT ro — Indication of Return from DP Interrupt Source
    values as DPUSR1R.DVBSTSH
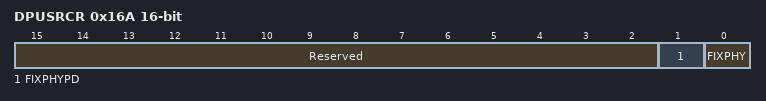
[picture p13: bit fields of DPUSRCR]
0x16A DPUSRCR 16-bit — Deep Standby USB Suspend/Resume Command Register
  [15:2] Reserved — These bits are read as 00000000000000. The write value should be 00000000000000.
  [1] FIXPHYPD — USB Transceiver Control Fix for PLL
    0=Normal mode; 1=Go to/Return from deep software standby mode
  [0] FIXPHY — USB Transceiver Control Fix
    values as FIXPHYPD
